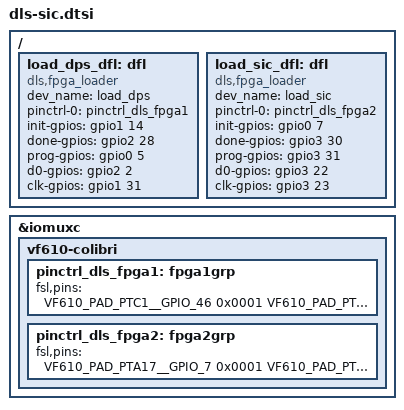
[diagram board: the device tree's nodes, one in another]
#include "dls-common.dtsi"

&iomuxc {
    vf610-colibri {
        pinctrl_dls_fpga1: fpga1grp {
            fsl,pins = <
                /* DPS ADC FPGA programming. */
                VF610_PAD_PTC1__GPIO_46     0x0001      // ADC INIT B
                VF610_PAD_PTD13__GPIO_92    0x0001      // ADC DONE
                VF610_PAD_PTA12__GPIO_5     0x00ed      // ADC PROG B
                VF610_PAD_PTD28__GPIO_66    0x00c1      // ADC DSO
                VF610_PAD_PTD31__GPIO_63    0x00cd      // ADC CLK
            >;
        };

        pinctrl_dls_fpga2: fpga2grp {
            fsl,pins = <
                /* Digital Interface FPGA programming. */
                VF610_PAD_PTA17__GPIO_7     0x0001      // INIT B
                VF610_PAD_PTE21__GPIO_126   0x0001      // DONE
                VF610_PAD_PTE22__GPIO_127   0x00ed      // PROG B
                VF610_PAD_PTE13__GPIO_118   0x00c1      // DSO
                VF610_PAD_PTE14__GPIO_119   0x00cd      // CLK
            >;
        };
    };
};

/ {
    load_dps_dfl: dfl {
        compatible = "dls,fpga_loader";
        dev_name = "load_dps";
        pinctrl-names = "default";
        pinctrl-0 = <&pinctrl_dls_fpga1>;
        init-gpios = <&gpio1 14 GPIO_ACTIVE_HIGH>;
        done-gpios = <&gpio2 28 GPIO_ACTIVE_HIGH>;
        prog-gpios = <&gpio0 5 GPIO_ACTIVE_HIGH>;
        d0-gpios = <&gpio2 2 GPIO_ACTIVE_HIGH>;
        clk-gpios = <&gpio1 31 GPIO_ACTIVE_HIGH>;
        status = "okay";
    };

    load_sic_dfl: dfl {
        compatible = "dls,fpga_loader";
        dev_name = "load_sic";
        pinctrl-names = "default";
        pinctrl-0 = <&pinctrl_dls_fpga2>;
        init-gpios = <&gpio0 7 GPIO_ACTIVE_HIGH>;
        done-gpios = <&gpio3 30 GPIO_ACTIVE_HIGH>;
        prog-gpios = <&gpio3 31 GPIO_ACTIVE_HIGH>;
        d0-gpios = <&gpio3 22 GPIO_ACTIVE_HIGH>;
        clk-gpios = <&gpio3 23 GPIO_ACTIVE_HIGH>;
        status = "okay";
    };
};
